# LPC12D27 register map
File version: 3
Registers are 32-bit, read-write, reset 0x0 unless marked. A register's access mark holds for its fields unless they carry their own. Offsets are from the block's base; lines under a group give offsets from that group; [hi:lo] are bit positions; {n}, {i} and the like mark numbered series; 'fields as' and 'values as' point back to an identical list; <NAME> marks a mode.

## Memory map
0x40000000 I2C size 0xFFF — Product name title=UM10441 Chapter title=LPC122x I2C-bus controller Modification date=2/2/2011 Major revision=0 Minor revision=17
0x40004000 WWDT size 0xFFF — Product name title=UM10441 Chapter title=LPC122x Windowed Watchdog Timer (WWDT) Modification date=2/2/2011 Major revision=0 Minor revision=17
0x40008000 UART0 size 0xFFF — Product name title=UM10441 Chapter title=LPC122x UART0 with modem control Modification date=2/2/2011 Major revision=0 Minor revision=17
0x4000C000 UART1 size 0xFFF — Product name title=UM10441 Chapter title=LPC122x UART1 Modification date=2/3/2011 Major revision=0 Minor revision=17
0x40010000 CT16B0 size 0xFFF — Product name title=UM10441 Chapter title=LPC122x 16-bit Counter/timer 0/1 (CT16B0/1) Modification date=2/3/2011 Major revision=0 Minor revision=17
0x40014000 CT16B1 size 0xFFF
0x40018000 CT32B0 size 0xFFF — Product name title=UM10441 Chapter title=LPC122x 32-bit Counter/timer 0/1 (CT32B0/1) Modification date=2/3/2011 Major revision=0 Minor revision=17
0x4001C000 CT32B1 size 0xFFF
0x40020000 ADC size 0xFFF — Product name title=UM10441 Chapter title=LPC122x ADC Modification date=2/9/2011 Major revision=0 Minor revision=17
0x40038000 PMU size 0xFFF — Product name title=UM10441 Chapter title=LPC122x Power Monitor Unit (PMU) Modification date=2/10/2011 Major revision=0 Minor revision=17
0x40040000 SSP size 0xFFF — Product name title=UM10441 Chapter title=LPC122x SSP controller Modification date=2/10/2011 Major revision=0 Minor revision=17
0x40044000 IOCON size 0xFFF — Product name title=UM10441 Chapter title=LPC122x I/O configuration (IOCONFIG) Modification date=8/18/2011 Major revision=2 Minor revision=0
0x40048000 SYSCON size 0xFFF — Product name title=UM10441 Chapter title=LPC122x System control (SYSCON) Modification date=8/18/2011 Major revision=2 Minor revision=0
0x4004C000 MICRO_DMA size 0xFFF — Product name title=UM10441 Chapter title=LPC122x General purpose micro DMA controller Modification date=2/10/2011 Major revision=0 Minor revision=17
0x40050000 RTC size 0xFFF — Product name title=UM10441 Chapter title=LPC122x Real-Time Clock (RTC) Modification date=2/11/2011 Major revision=1 Minor revision=0
0x40054000 ACOMP size 0xFFF — Product name title=UM10441 Chapter title=LPC122x Comparator Modification date=2/11/2011 Major revision=0 Minor revision=17
0x50000000 GPIO0 size 0xFFFF — Product name title=UM10441 Chapter title=LPC122x General Purpose I/O (GPIO) Modification date=2/11/2011 Major revision=0 Minor revision=17
0x50010000 GPIO1 size 0xFFFF — Product name title=UM10441 Chapter title=LPC122x General Purpose I/O (GPIO) Modification date=2/11/2011 Major revision=0 Minor revision=17
0x50020000 GPIO2 size 0xFFFF — Product name title=UM10441 Chapter title=LPC122x General Purpose I/O (GPIO) Modification date=2/11/2011 Major revision=0 Minor revision=17
0x50060000 FLASHCTRL size 0xFFF — Product name title=UM10441 Chapter title=LPC122x System control (SYSCON) Modification date=2/16/2011 Major revision=1 Minor revision=0
0x50070000 CRC size 0xFFFF — Product name title=UM10441 Chapter title=LPC122x CRC engine Modification date=2/11/2011 Major revision=0 Minor revision=17

## Interrupts
{n} START_PIO0_{n} (SYSCON) (n=0..11)
12 I2C
13 CT16B0
14 CT16B1
15 CT32B0
16 CT32B1
17 SSP
18 UART0
19 UART1
20 ACOMP
21 ADC
22 WDT (WWDT)
23 BOD (SYSCON)
25 PIO0 (GPIO0)
26 PIO1 (GPIO1)
27 PIO2 (GPIO2)
29 DMA (MICRO_DMA)
30 RTC

## PMU — Product name title=UM10441 Chapter title=LPC122x Power Monitor Unit (PMU) Modification date=2/10/2011 Major revision=0 Minor revision=17
Base 0x40038000
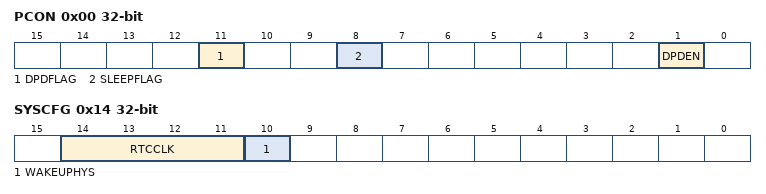
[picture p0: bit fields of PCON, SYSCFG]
0x00 PCON — Power control register
  [11] DPDFLAG — Deep power-down flag
    0=READ_DEEP_POWER_DOW (Read: Deep power-down mode not entered. Write: No effect.); 1=CLEAR (Read: Deep power-down mode entered. Write: Clear the Deep power-down flag.)
  [8] SLEEPFLAG — Sleep mode flag
    0=READ_NO_POWER_DOWN_ (Read: No power-down mode entered. LPC1xxx is in Run mode. Write: No effect.); 1=CLEAR (Read: Sleep/Deep-sleep or Deep power-down mode entered. Write: Writing a 1 clears the SLEEPFLAG bit to 0.)
  [1] DPDEN — Deep power-down mode enable
    0=DEEP_SLEEP (ARM WFI will enter Sleep or Deep-sleep mode (clock to ARM Cortex-M0 core turned off).); 1=DEEP_POWERDOWN (ARM WFI will enter Deep-power down mode (ARM Cortex-M0 core powered-down) if WDLOCKDP = 0 .)
{0x4+4i} GPREG{i} (i=0..3) — General purpose register
  [31:0] GPDATA — Data retained during Deep power-down mode.
0x14 SYSCFG — System configuration register (RTC clock control and hysteresis of the WAKEUP pin).
  [14:11] RTCCLK — RTC clock source select (X = don't care). 0000 = 1 Hz clock 0001 = delayed 1 Hz clock 101X = 1 kHz clock 01XX = RTC PCLK (main clock divided by the RTC clock divider value)
  [10] WAKEUPHYS — WAKEUP pin hysteresis enable
    0=DISABLED (Hysteresis for WAKUP pin disabled.); 1=ENABLED (Hysteresis for WAKEUP pin enabled.)
